# MSP430F1611 register map
Registers are 8-bit, read-write, reset 0x0 unless marked. A register's access mark holds for its fields unless they carry their own. Offsets are from the block's base; [hi:lo] are bit positions; lines under a group give offsets from that group; {n}, {i} and the like mark numbered series; 'fields as' and 'values as' point back to an identical list.

## WATCHDOG_TIMER
Base 0x00000120
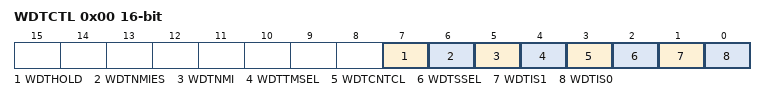
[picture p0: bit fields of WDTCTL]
0x00 WDTCTL 16-bit — Watchdog Timer Control
  [7] WDTHOLD, [6] WDTNMIES, [5] WDTNMI, [4] WDTTMSEL, [3] WDTCNTCL, [2] WDTSSEL, [1] WDTIS1, [0] WDTIS0

## FLASH
Base 0x00000128
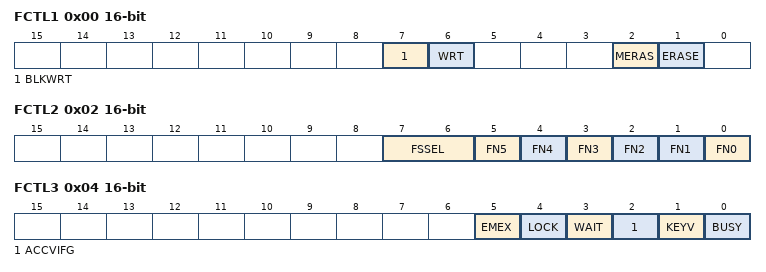
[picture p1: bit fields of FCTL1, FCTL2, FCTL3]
0x00 FCTL1 16-bit — FLASH Control 1
  [7] BLKWRT — Enable bit for Flash segment write
  [6] WRT — Enable bit for Flash write
  [2] MERAS — Enable bit for Flash mass erase
  [1] ERASE — Enable bit for Flash segment erase
0x02 FCTL2 16-bit — FLASH Control 2
  [7:6] FSSEL — Flash clock select 0 */ /* to distinguish from USART SSELx
    0=Flash clock select: 0 - ACLK; 1=Flash clock select: 1 - MCLK; 2=Flash clock select: 2 - SMCLK; 3=Flash clock select: 3 - SMCLK
  [n] FN{n} (n=2..5)
  [1] FN1 — 32*FN5 + 16*FN4 + 8*FN3 + 4*FN2 + 2*FN1 + FN0 + 1
  [0] FN0 — Divide Flash clock by 1 to 64 using FN0 to FN5 according to:
0x04 FCTL3 16-bit — FLASH Control 3
  [5] EMEX — Flash Emergency Exit
  [4] LOCK — Lock bit: 1 - Flash is locked (read only)
  [3] WAIT — Wait flag for segment write
  [2] ACCVIFG — Flash Access violation flag
  [1] KEYV — Flash Key violation flag
  [0] BUSY — Flash busy: 1

## TIMER_A3
Base 0x0000012E
0x00 TAIV 16-bit — Timer A Interrupt Vector Word
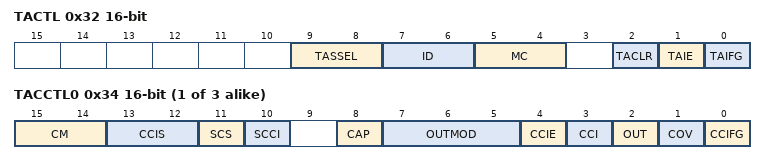
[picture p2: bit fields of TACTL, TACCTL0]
0x32 TACTL 16-bit — Timer A Control
  [9:8] TASSEL — Timer A clock source select 1
    0=Timer A clock source select: 0 - TACLK; 1=Timer A clock source select: 1 - ACLK; 2=Timer A clock source select: 2 - SMCLK; 3=Timer A clock source select: 3 - INCLK
  [7:6] ID — Timer A clock input divider 1
    0=Timer A input divider: 0 - /1; 1=Timer A input divider: 1 - /2; 2=Timer A input divider: 2 - /4; 3=Timer A input divider: 3 - /8
  [5:4] MC — Timer A mode control 1
    0=Timer A mode control: 0 - Stop; 1=Timer A mode control: 1 - Up to CCR0; 2=Timer A mode control: 2 - Continous up; 3=Timer A mode control: 3 - Up/Down
  [2] TACLR — Timer A counter clear
  [1] TAIE — Timer A counter interrupt enable
  [0] TAIFG — Timer A counter interrupt flag
{0x34+2i} TACCTL{i} 16-bit (i=0..2) — Timer A Capture/Compare Control {i}
  [15:14] CM — Capture mode 1
    0=Capture mode: 0 - disabled; 1=Capture mode: 1 - pos. edge; 2=Capture mode: 1 - neg. edge; 3=Capture mode: 1 - both edges
  [13:12] CCIS — Capture input select 1
    0=Capture input select: 0 - CCIxA; 1=Capture input select: 1 - CCIxB; 2=Capture input select: 2 - GND; 3=Capture input select: 3 - Vcc
  [11] SCS — Capture sychronize
  [10] SCCI — Latched capture signal (read)
  [8] CAP — Capture mode: 1 /Compare mode : 0
  [7:5] OUTMOD — Output mode 2
    0=PWM output mode: 0 - output only; 1=PWM output mode: 1 - set; 2=PWM output mode: 2 - PWM toggle/reset; 3=PWM output mode: 3 - PWM set/reset; 4=PWM output mode: 4 - toggle; 5=PWM output mode: 5 - Reset; 6=PWM output mode: 6 - PWM toggle/set; 7=PWM output mode: 7 - PWM reset/set
  [4] CCIE — Capture/compare interrupt enable
  [3] CCI — Capture input signal (read)
  [2] OUT — PWM Output signal if output mode 0
  [1] COV — Capture/compare overflow flag
  [0] CCIFG — Capture/compare interrupt flag
0x42 TAR 16-bit — Timer A Counter Register
{0x44+2i} TACCR{i} 16-bit (i=0..2) — Timer A Capture/Compare {i}

## MULTIPLIER
Base 0x00000130
0x00 MPY 16-bit — Multiply Unsigned/Operand 1
0x02 MPYS 16-bit — Multiply Signed/Operand 1
0x04 MAC 16-bit — Multiply Unsigned and Accumulate/Operand 1
0x06 MACS 16-bit — Multiply Signed and Accumulate/Operand 1
0x08 OP2 16-bit — Operand 2
0x0A RESLO 16-bit — Result Low Word
0x0C RESHI 16-bit — Result High Word
0x0E SUMEXT 16-bit — Sum Extend

## DAC12
Base 0x000001C0
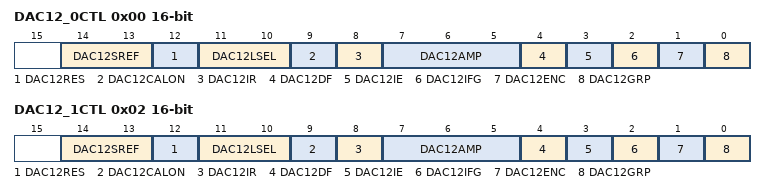
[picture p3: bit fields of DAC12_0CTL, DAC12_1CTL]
0x00 DAC12_0CTL 16-bit — DAC12_0 Control
  [14:13] DAC12SREF — DAC12 reference bit 0
    0=DAC12 reference 0: Vref+; 1=DAC12 reference 1: Vref+; 2=DAC12 reference 2: Veref+; 3=DAC12 reference 3: Veref+
  [12] DAC12RES — DAC12 resolution
  [11:10] DAC12LSEL — DAC12 load select bit 0
    0=DAC12 load select 0: direct; 1=DAC12 load select 1: latched with DAT; 2=DAC12 load select 2: latched with pos. Timer_A3.OUT1; 3=DAC12 load select 3: latched with pos. Timer_B7.OUT1
  [9] DAC12CALON — DAC12 calibration
  [8] DAC12IR — DAC12 input reference and output range
  [7:5] DAC12AMP — DAC12 amplifier bit 0
    0=DAC12 amplifier 0: off; 1=DAC12 amplifier 1: off; 2=DAC12 amplifier 2: low; 3=DAC12 amplifier 3: low; 4=DAC12 amplifier 4: low; 5=DAC12 amplifier 5: medium; 6=DAC12 amplifier 6: medium; 7=DAC12 amplifier 7: high
  [4] DAC12DF — DAC12 data format
  [3] DAC12IE — DAC12 interrupt enable
  [2] DAC12IFG — DAC12 interrupt flag
  [1] DAC12ENC — DAC12 enable conversion
  [0] DAC12GRP — DAC12 group
0x02 DAC12_1CTL 16-bit — DAC12_1 Control
  fields as DAC12_0CTL
0x08 DAC12_0DAT 16-bit — DAC12_0 Data
0x0A DAC12_1DAT 16-bit — DAC12_1 Data
